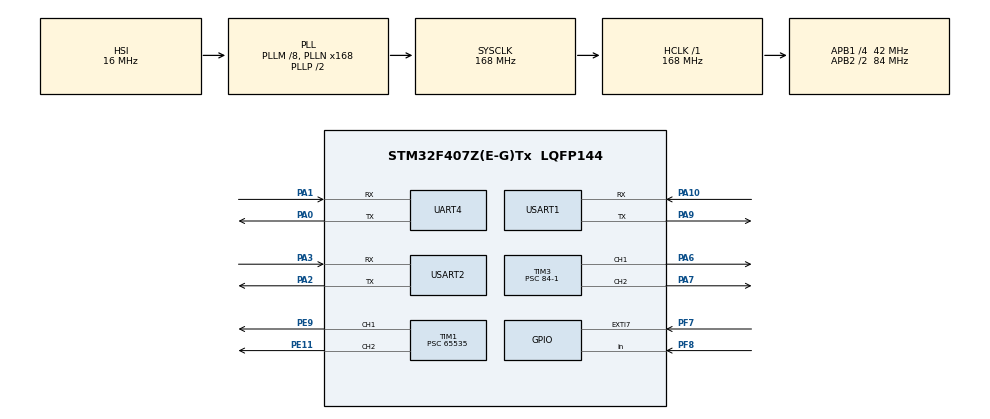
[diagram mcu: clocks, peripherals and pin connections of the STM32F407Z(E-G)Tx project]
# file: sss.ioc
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Dma.Request0=USART2_TX
Dma.USART2_TX.0.Direction=DMA_MEMORY_TO_PERIPH
Dma.USART2_TX.0.FIFOMode=DMA_FIFOMODE_DISABLE
Dma.USART2_TX.0.Instance=DMA1_Stream6
Dma.USART2_TX.0.MemDataAlignment=DMA_MDATAALIGN_BYTE
Dma.USART2_TX.0.MemInc=DMA_MINC_ENABLE
Dma.USART2_TX.0.Mode=DMA_NORMAL
Dma.USART2_TX.0.PeriphDataAlignment=DMA_PDATAALIGN_BYTE
Dma.USART2_TX.0.PeriphInc=DMA_PINC_DISABLE
Dma.USART2_TX.0.Priority=DMA_PRIORITY_LOW
Mcu.Family=STM32F4
Mcu.Name=STM32F407Z(E-G)Tx
Mcu.Package=LQFP144
NVIC.DMA1_Stream6_IRQn=true\:0\:0\:false\:false\:true\:false\:true\:true
NVIC.EXTI9_5_IRQn=true\:0\:0\:false\:false\:true\:true\:true\:true
NVIC.PriorityGroup=NVIC_PRIORITYGROUP_4
NVIC.TIM2_IRQn=true\:0\:0\:true\:false\:true\:true\:true\:true
NVIC.USART1_IRQn=true\:0\:0\:true\:false\:true\:true\:true\:true
NVIC.USART2_IRQn=true\:0\:0\:false\:false\:true\:true\:true\:true
PA0-WKUP.Mode=Asynchronous
PA0-WKUP.Signal=UART4_TX
PA1.Mode=Asynchronous
PA1.Signal=UART4_RX
PA10.Mode=Asynchronous
PA10.Signal=USART1_RX
PA13.Mode=Serial_Wire
PA13.Signal=SYS_JTMS-SWDIO
PA14.Mode=Serial_Wire
PA14.Signal=SYS_JTCK-SWCLK
PA2.Mode=Asynchronous
PA2.Signal=USART2_TX
PA3.Mode=Asynchronous
PA3.Signal=USART2_RX
PA6.Signal=S_TIM3_CH1
PA7.Signal=S_TIM3_CH2
PA9.Mode=Asynchronous
PA9.Signal=USART1_TX
PE11.Signal=S_TIM1_CH2
PE9.Signal=S_TIM1_CH1
PF7.GPIO_ModeDefaultEXTI=GPIO_MODE_IT_FALLING
PF7.GPIO_PuPd=GPIO_NOPULL
PF7.Signal=GPXTI7
PF8.GPIO_PuPd=GPIO_PULLUP
PF8.Signal=GPIO_Input
PH0-OSC_IN.Mode=HSE-External-Oscillator
PH0-OSC_IN.Signal=RCC_OSC_IN
PH1-OSC_OUT.Mode=HSE-External-Oscillator
PH1-OSC_OUT.Signal=RCC_OSC_OUT
ProjectManager.HeapSize=0x200
ProjectManager.StackSize=0x400
ProjectManager.TargetToolchain=MDK-ARM V5.32
RCC.48MHZClocksFreq_Value=84000000
RCC.AHBFreq_Value=168000000
RCC.APB1CLKDivider=RCC_HCLK_DIV4
RCC.APB1Freq_Value=42000000
RCC.APB1TimFreq_Value=84000000
RCC.APB2CLKDivider=RCC_HCLK_DIV2
RCC.APB2Freq_Value=84000000
RCC.APB2TimFreq_Value=168000000
RCC.CortexFreq_Value=168000000
RCC.HCLKFreq_Value=168000000
RCC.HSE_VALUE=25000000
RCC.HSI_VALUE=16000000
RCC.LSE_VALUE=32768
RCC.PLLM=8
RCC.PLLN=168
RCC.SYSCLKFreq_VALUE=168000000
RCC.SYSCLKSource=RCC_SYSCLKSOURCE_PLLCLK
RCC.VCOOutputFreq_Value=336000000
SH.S_TIM1_CH1.0=TIM1_CH1,Output Compare1 CH1
SH.S_TIM1_CH2.0=TIM1_CH2,Output Compare2 CH2
SH.S_TIM3_CH1.0=TIM3_CH1,PWM Generation1 CH1
SH.S_TIM3_CH2.0=TIM3_CH2,PWM Generation2 CH2
TIM1.Channel-Output\ Compare1\ CH1=TIM_CHANNEL_1
TIM1.Channel-Output\ Compare2\ CH2=TIM_CHANNEL_2
TIM1.Prescaler=65535
TIM2.AutoReloadPreload=TIM_AUTORELOAD_PRELOAD_ENABLE
TIM2.Period=100000-1
TIM2.Prescaler=84-1
TIM3.AutoReloadPreload=TIM_AUTORELOAD_PRELOAD_ENABLE
TIM3.Channel-PWM\ Generation1\ CH1=TIM_CHANNEL_1
TIM3.Channel-PWM\ Generation2\ CH2=TIM_CHANNEL_2
TIM3.Period=20000-1
TIM3.Prescaler=84-1
UART4.VirtualMode=Asynchronous
USART1.VirtualMode=VM_ASYNC
USART2.VirtualMode=VM_ASYNC
VP_TIM1_VS_ClockSourceINT.Mode=Internal
VP_TIM2_VS_ClockSourceINT.Mode=Internal
VP_TIM3_VS_ClockSourceINT.Mode=Internal
board=custom

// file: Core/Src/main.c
/* USER CODE BEGIN Header */
/**
  ******************************************************************************
  * @file           : main.c
  * @brief          : Main program body
  ******************************************************************************
  * @attention
  *
  * Copyright (c) 2024 STMicroelectronics.
  * All rights reserved.
  *
  * This software is licensed under terms that can be found in the LICENSE file
  * in the root directory of this software component.
  * If no LICENSE file comes with this software, it is provided AS-IS.
  *
  ******************************************************************************
  */
/* USER CODE END Header */
#include "main.h"

/* USER CODE BEGIN PV */
uint8_t ch = 0;
/* USER CODE END PV */

void SystemClock_Config(void);

/* USER CODE BEGIN 0 */

int fputc(int ch ,FILE *f)
{
	//轮询方式发�?�一个字节数�?
	HAL_UART_Transmit (&huart1 ,(uint8_t *)&ch , 1,HAL_MAX_DELAY );
	return ch ;
}

/* USER CODE END 0 */

int main(void)
{

  /* MCU Configuration--------------------------------------------------------*/

  /* Reset of all peripherals, Initializes the Flash interface and the Systick. */
  HAL_Init();

  /* Configure the system clock */
  SystemClock_Config();

  /* Initialize all configured peripherals */
  MX_GPIO_Init();
  MX_TIM1_Init();
  MX_UART4_Init();
  MX_DMA_Init();
  MX_USART1_UART_Init();
  MX_USART2_UART_Init();
  MX_TIM2_Init();
  MX_TIM3_Init();
  /* USER CODE BEGIN 2 */

  HAL_TIM_Base_Start(&htim1);
  HAL_TIM_Base_Start_IT(&htim2);
  HAL_UART_Receive_IT(&huart1, (uint8_t *)&USART1_RXbuff, 1); //uart1???openmv

  /* USER CODE END 2 */

  /* Infinite loop */
  while (1)
  {
  }
}

void SystemClock_Config(void)
{
  RCC_OscInitTypeDef RCC_OscInitStruct = {0};
  RCC_ClkInitTypeDef RCC_ClkInitStruct = {0};

  /** Configure the main internal regulator output voltage
  */
  __HAL_RCC_PWR_CLK_ENABLE();
  __HAL_PWR_VOLTAGESCALING_CONFIG(PWR_REGULATOR_VOLTAGE_SCALE1);

  /** Initializes the RCC Oscillators according to the specified parameters
  * in the RCC_OscInitTypeDef structure.
  */
  RCC_OscInitStruct.OscillatorType = RCC_OSCILLATORTYPE_HSI;
  RCC_OscInitStruct.HSIState = RCC_HSI_ON;
  RCC_OscInitStruct.HSICalibrationValue = RCC_HSICALIBRATION_DEFAULT;
  RCC_OscInitStruct.PLL.PLLState = RCC_PLL_ON;
  RCC_OscInitStruct.PLL.PLLSource = RCC_PLLSOURCE_HSI;
  RCC_OscInitStruct.PLL.PLLM = 8;
  RCC_OscInitStruct.PLL.PLLN = 168;
  RCC_OscInitStruct.PLL.PLLP = RCC_PLLP_DIV2;
  RCC_OscInitStruct.PLL.PLLQ = 4;
  if (HAL_RCC_OscConfig(&RCC_OscInitStruct) != HAL_OK)
  {
    Error_Handler();
  }

  /** Initializes the CPU, AHB and APB buses clocks
  */
  RCC_ClkInitStruct.ClockType = RCC_CLOCKTYPE_HCLK|RCC_CLOCKTYPE_SYSCLK
                              |RCC_CLOCKTYPE_PCLK1|RCC_CLOCKTYPE_PCLK2;
  RCC_ClkInitStruct.SYSCLKSource = RCC_SYSCLKSOURCE_PLLCLK;
  RCC_ClkInitStruct.AHBCLKDivider = RCC_SYSCLK_DIV1;
  RCC_ClkInitStruct.APB1CLKDivider = RCC_HCLK_DIV4;
  RCC_ClkInitStruct.APB2CLKDivider = RCC_HCLK_DIV2;

  if (HAL_RCC_ClockConfig(&RCC_ClkInitStruct, FLASH_LATENCY_5) != HAL_OK)
  {
    Error_Handler();
  }
}

void Error_Handler(void)
{
  __disable_irq();
  while (1)
  {
  }
}
